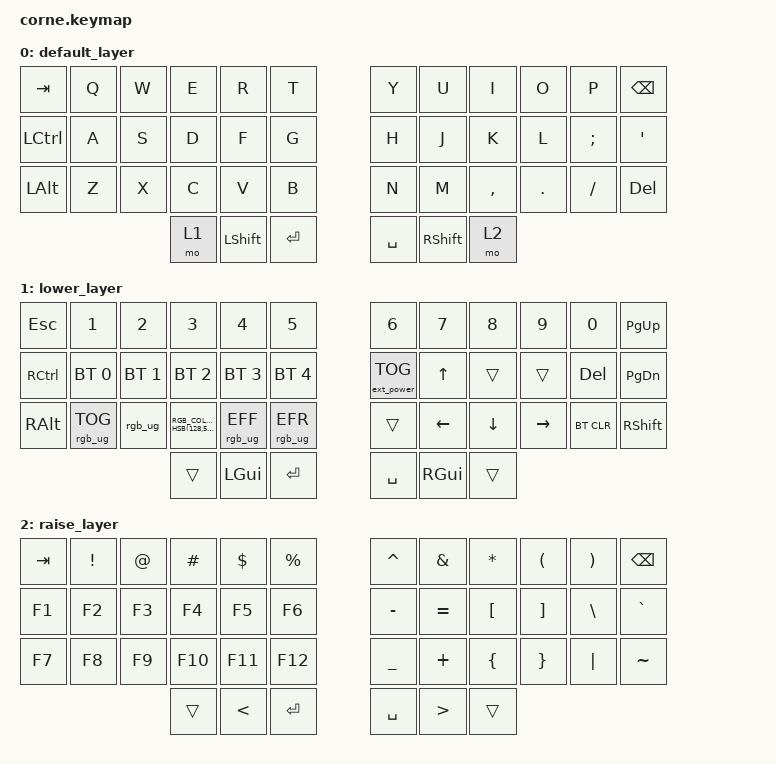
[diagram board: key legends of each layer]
/*
 * Copyright (c) 2020 The ZMK Contributors
 *
 * SPDX-License-Identifier: MIT
 */

#include <behaviors.dtsi>
#include <dt-bindings/zmk/keys.h>
#include <dt-bindings/zmk/bt.h>
#include <dt-bindings/zmk/rgb.h>
#include <dt-bindings/zmk/ext_power.h>


    &led_strip {
        chain-length = <27>;
    };

/ {
    keymap {
                compatible = "zmk,keymap";

                default_layer {
// -----------------------------------------------------------------------------------------
// |  TAB |  Q  |  W  |  E  |  R  |  T  |   |  Y  |  U   |  I  |  O  |  P  | BSPC |
// | LCTRL |  A  |  S  |  D  |  F  |  G  |   |  H  |  J   |  K  |  L  |  ;  |  '   |
// | LSHIFT |  Z  |  X  |  C  |  V  |  B  |   |  N  |  M   |  ,  |  .  |  /  | RSHIFT  |
//                    | LGUI | LWR | ENT |   | SPACE | RSE  | ALT |
                        bindings = <
   &kp TAB   &kp Q &kp W &kp E &kp R &kp T   &kp Y &kp U  &kp I     &kp O   &kp P    &kp BSPC
   &kp LCTRL &kp A &kp S &kp D &kp F &kp G   &kp H &kp J  &kp K     &kp L   &kp SEMI &kp SQT
   &kp LALT &kp Z &kp X &kp C &kp V &kp B   &kp N &kp M  &kp COMMA &kp DOT &kp FSLH &kp DEL
                  &mo 1 &kp LSHIFT &kp RET   &kp SPACE &kp RSHIFT &mo 2 
                        >;
                };
                lower_layer {
// -----------------------------------------------------------------------------------------
// |  ESC |  1  |  2  |  3  |  4  |  5  |   |  6  |  7  |  8  |  9  |  0  | PG_UP |
// | RCTRL| BT1 | BT2 | BT3 | BT4 | BT5 |   |     |  UP |     |     |     | PG_DN |
// | LSHIFT |     |     |     |     |     |   | LFT | DWN | RGT |     |     | RSHIFT |
//                    | GUI |     | ENTER |   | SPC |     | ALT |
                        bindings = <
   &kp ESC     &kp N1           &kp N2       &kp N3       &kp N4       &kp N5         &kp N6   &kp N7   &kp N8 &kp N9    &kp N0 &kp PG_UP
   &kp RCTRL   &bt BT_SEL 0     &bt BT_SEL 1 &bt BT_SEL 2 &bt BT_SEL 3 &bt BT_SEL 4   &ext_power EP_TOG &kp UP &trans &trans &kp DEL &kp PG_DN
   &kp RALT  &rgb_ug RGB_TOG  &rgb_ug RGB_COLOR_HSB(128,50,128)  &rgb_ug RGB_EFF &rgb_ug RGB_EFR      &trans &kp LEFT   &kp DOWN   &kp RIGHT &bt BT_CLR &kp RSHIFT
                                    &trans   &kp LGUI  &kp RET      &kp SPACE  &kp RGUI  &trans  
                        >;
                };

                raise_layer {
// -----------------------------------------------------------------------------------------
// |  TAB |  !  |  @  |  #  |  $  |  %        |   |  ^  |  &  |  *  |  (  |  )  | BSPC |
// | F1 |  F2 |  F3   | F4  |  F5   |  F6     |   |  -  |  =  |  [  |  ]  |  \  |  `   |
// | F7 |  F8  | F9    | F10  | F11    | F12  |   |  _  |  +  |  {  |  }  | "|" |  ~   |
//                    | GUI |     | SPC |   | ENT |     | ALT |
                        bindings = <
   &kp TAB  &kp EXCL  &kp AT &kp HASH &kp DLLR &kp PRCNT     &kp CARET &kp AMPS  &kp ASTRK &kp LPAR &kp RPAR &kp BSPC
   &kp F1    &kp F2   &kp F3 &kp F4   &kp F5  &kp F6         &kp MINUS &kp EQUAL &kp LBKT  &kp RBKT &kp BSLH &kp GRAVE
   &kp F7    &kp F8   &kp F9 &kp F10   &kp F11 &kp F12         &kp UNDER &kp PLUS  &kp LBRC  &kp RBRC &kp PIPE &kp TILDE
                            &trans  &kp LT   &kp RET       &kp SPACE   &kp GT &trans 
                        >;
                };
        };
};
    
